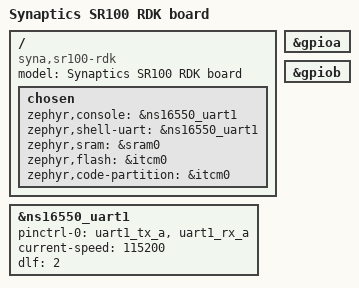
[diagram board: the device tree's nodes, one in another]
/*
 * Copyright (c) 2025 Synaptics, Inc.
 *
 * SPDX-License-Identifier: Apache-2.0
 */

/dts-v1/;
#include <syna/sr100.dtsi>
#include <syna/sr100_pinctrl.dtsi>
#include <zephyr/dt-bindings/gpio/gpio.h>
#include <zephyr/dt-bindings/input/input-event-codes.h>

/ {
	model = "Synaptics SR100 RDK board";
	compatible = "syna,sr100-rdk";

	chosen {
		zephyr,console = &ns16550_uart1;
		zephyr,shell-uart = &ns16550_uart1;
		zephyr,sram = &sram0;
		zephyr,flash = &itcm0;
		zephyr,code-partition = &itcm0;
	};
};

&ns16550_uart1 {
	pinctrl-0 = <&uart1_tx_a &uart1_rx_a>;
	pinctrl-names = "default";
	current-speed = <115200>;
	dlf = <2>;
	status = "okay";
};

&gpioa {
	status = "okay";
};

&gpiob {
	status = "okay";
};
